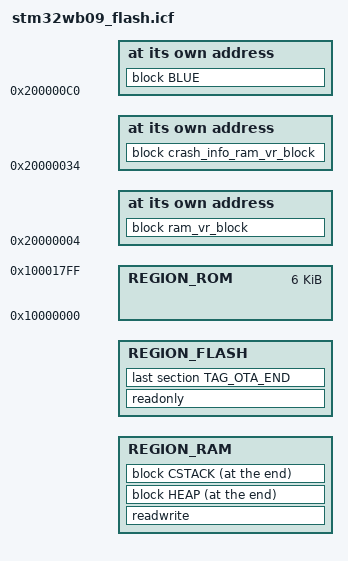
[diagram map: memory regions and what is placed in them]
/*******************************************************************************
* STM32WB09 generic linker file for IAR
* Main linker variables to control it are:
*
* MEMORY_FLASH_APP_SIZE: define the size of the application in case not all the flash is needed.
* Default value is: 508KB
*
* MEMORY_FLASH_APP_OFFSET: define the offset of the application.
* Default value is: 0 offset
*
* MEMORY_RAM_APP_OFFSET: define the offset in RAM from which sections can be
* allocated.
* Default value is: 0 offset
* 
*******************************************************************************/

/*******************************************************************************
* Memory Definitions
*******************************************************************************/
/*
STM32WB09 memory map
+-----------------------+ 0x2000FFFF
|  RAM (64K)            |
+-----------------------+ 0x20000000
|                       |
|                       |
+-----------------------+ 0x100BFFFF
|                       |
|  NVM(4K)              |
+-----------------------+ 0x100BEFFF
|                       |
|  User app (508K)      |
+-----------------------+ 0x10040000
|                       |
+-----------------------| 0x100017FF
|   ROM (6K)            |
+-----------------------+ 0x10000000
*/

define symbol _MEMORY_RAM_BEGIN_      = 0x20000000;
define symbol _MEMORY_RAM_SIZE_       = 0x10000;      /* 64KB  */
define symbol _MEMORY_RAM_END_        = 0x2000FFFF;

define symbol _MEMORY_FLASH_BEGIN_    = 0x10040000;
define symbol _MEMORY_FLASH_SIZE_     = 0x80000;      /* 512KB */
define symbol _MEMORY_FLASH_END_      = 0x100BFFFF; 

define symbol _MEMORY_ROM_BEGIN_      = 0x10000000;
define symbol _MEMORY_ROM_SIZE_       = 0x01800;      /* 6KB */ 
define symbol _MEMORY_ROM_END_        = 0x100017FF; 
      

/* Reserved for BTLE stack non volatile memory */
define symbol FLASH_NVM_DATASIZE       = (4*1024);

if( !isdefinedsymbol( MEMORY_RAM_APP_OFFSET) ) {
  define symbol MEMORY_RAM_APP_OFFSET = (0x00);
}

if( !isdefinedsymbol( MEMORY_FLASH_APP_OFFSET) ) {
  define symbol MEMORY_FLASH_APP_OFFSET = 0;
}
if( !isdefinedsymbol( MEMORY_FLASH_APP_SIZE) ) {
  define symbol MEMORY_FLASH_APP_SIZE   = (_MEMORY_FLASH_SIZE_ - FLASH_NVM_DATASIZE - MEMORY_FLASH_APP_OFFSET);
}


/*******************************************************************************
* Memory Definitions
*******************************************************************************/

define memory mem with size = 4G;   /* This is mandatory for the IAR linker.  */
                                    /* It creates a memory space "mem" with   */
                                    /* 4 gigabytes. 32-bit data bus always    */
                                    /* means 4G memory space.                 */

/* region definitions */
define region REGION_RAM   = mem:[from _MEMORY_RAM_BEGIN_ + MEMORY_RAM_APP_OFFSET
                                   to _MEMORY_RAM_END_];
                                   
define region REGION_FLASH = mem:[from _MEMORY_FLASH_BEGIN_ + MEMORY_FLASH_APP_OFFSET
                                  to  _MEMORY_FLASH_BEGIN_ + MEMORY_FLASH_APP_OFFSET + MEMORY_FLASH_APP_SIZE - 1];

define region REGION_FLASH_NVM = mem:[from _MEMORY_FLASH_END_- FLASH_NVM_DATASIZE + 1
                                  to   _MEMORY_FLASH_END_];
define region REGION_ROM = mem:[from _MEMORY_ROM_BEGIN_ to  _MEMORY_ROM_END_];


/*******************************************************************************
* STM32WB09 STACK Sections
*******************************************************************************/
define block BLUE with alignment = 8  { section .bss.__blue_RAM}; // Radio Global configuration data
keep {section .bss.__blue_RAM};
place at address mem: 0x200000C0 { block BLUE, };

/*******************************************************************************
* FLASH Sections
*******************************************************************************/
place at start of REGION_FLASH { block FlashStart with fixed order {readonly section .intvec, readonly section TAG_OTA_START} };
keep {section .intvec};
keep {section TAG_OTA_START};
keep {section TAG_OTA_END};

/*******************************************************************************
* RAM Sections
*******************************************************************************/

/*-Sizes-*/
define symbol __ICFEDIT_size_cstack__ = 0xC00;
define symbol __ICFEDIT_size_heap__   = 0x000;
/**** End of ICF editor section. ###ICF###*/

define block CSTACK    with alignment = 8, size = __ICFEDIT_size_cstack__   { };
define block HEAP      with alignment = 8, size = __ICFEDIT_size_heap__     { };

do not initialize { section CSTACK };

initialize by copy { readwrite };
do not initialize  {section .noinit};


/* RAM VR Block */             
define block ram_vr_block with alignment = 4 { section .ram_vr};
keep {section .ram_vr};
place at address mem: 0x20000004 { block ram_vr_block, };

/* Crash Handler Storage Information Block */
define symbol CRASH_RAM_SIZE             = 40;                  
define block crash_info_ram_vr_block with alignment = 4, size = CRASH_RAM_SIZE { section .crash_info_ram_vr};
keep {section .crash_info_ram_vr};
do not initialize  {section .crash_info_ram_vr};
place at address mem: 0x20000034 { block crash_info_ram_vr_block, };

/*******************************************************************************
* Sections placement
*******************************************************************************/
place in REGION_FLASH { readonly, last section TAG_OTA_END };
place in REGION_RAM { readwrite };
place at end of REGION_RAM {block HEAP, block CSTACK };

/*******************************************************************************
* End of File
*******************************************************************************/
